# CM41x_M4 register map
Vendor: Analog Devices; Series: CM41x_M4; File version: 1p0
CPU: CM4 r0p1, little endian, MPU, FPU, 4 interrupt priority bits
Registers are 32-bit, read-write, reset 0x0 unless marked. A register's access mark holds for its fields unless they carry their own. Offsets are from the block's base; [hi:lo] are bit positions; {n}, {i} and the like mark numbered series.

## SMC0 — Static Memory Controller
Base 0x4002F000
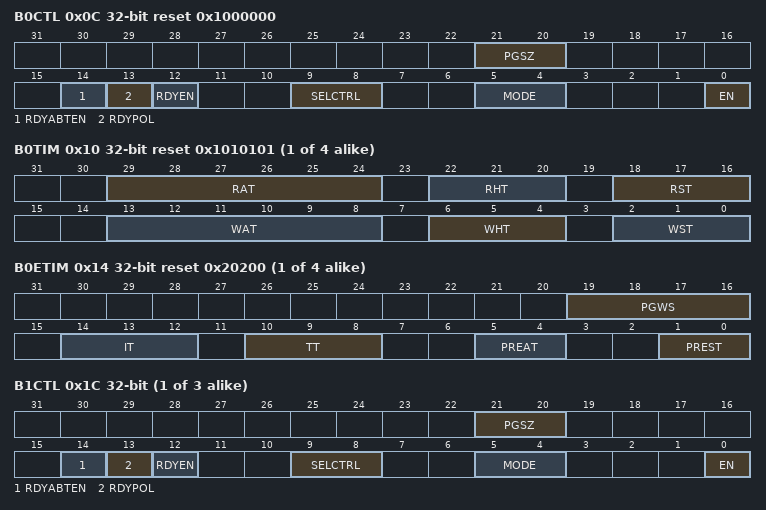
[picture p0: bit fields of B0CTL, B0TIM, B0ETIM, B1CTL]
0x0C B0CTL reset 0x1000000 — Bank 0 Control Register
  [21:20] PGSZ — Flash Page Size
  [14] RDYABTEN — ARDY Abort Enable
  [13] RDYPOL — ARDY Polarity
  [12] RDYEN — ARDY Enable
  [9:8] SELCTRL — Select Control
  [5:4] MODE — Memory Access Mode
  [0] EN — Bank 0 Enable
{0x10+0x10*i} B{i}TIM reset 0x1010101 (i=0..3) — Bank {i} Timing Register
  [29:24] RAT — Read Access Time
  [22:20] RHT — Read Hold Time
  [18:16] RST — Read Setup Time
  [13:8] WAT — Write Access Time
  [6:4] WHT — Write Hold Time
  [2:0] WST — Write Setup Time
{0x14+0x10*i} B{i}ETIM reset 0x20200 (i=0..3) — Bank {i} Extended Timing Register
  [19:16] PGWS — Page Wait States
  [14:12] IT — Idle Time
  [10:8] TT — Transition Time
  [5:4] PREAT — Pre Access Time
  [1:0] PREST — Pre Setup Time
{0xC+0x10*i} B{i}CTL (i=1..3) — Bank {i} Control Register
  [21:20] PGSZ — Flash Page Size
  [14] RDYABTEN — ARDY Abort Enable
  [13] RDYPOL — ARDY Polarity
  [12] RDYEN — ARDY Enable
  [9:8] SELCTRL — Select Control
  [5:4] MODE — Memory Access Mode
  [0] EN — Bank {i} Enable

## DACC0 — DAC Controller
Base 0x4004B000
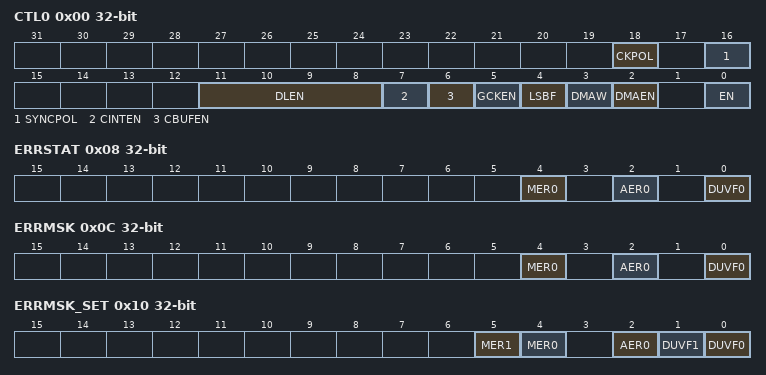
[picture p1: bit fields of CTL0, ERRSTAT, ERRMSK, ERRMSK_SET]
0x00 CTL0 — Control 0 Register
  [18] CKPOL — Clock Polarity
  [16] SYNCPOL — SYNC Polarity
  [11:8] DLEN range 0x00000000..0x0000000F — Data Length
  [7] CINTEN — Circular Buffer Interrupt Enable
  [6] CBUFEN — Circular Buffer Enable
  [5] GCKEN — Gated Clock Enable
  [4] LSBF — LSB-First Mode
  [3] DMAW — DMA Data Width
  [2] DMAEN — DMA Enable
  [0] EN — Enable
0x08 ERRSTAT — Error Status Register
  [4] MER0 — Memory Error 0
  [2] AER0 — Address Alignment Error 0
  [0] DUVF0 — DAC0 Underflow
0x0C ERRMSK — Error Mask Register
  [4] MER0 — Memory Error 0 Mask
  [2] AER0 — Address Alignment Error 0 Mask
  [0] DUVF0 — DAC Underflow 0 Mask
0x10 ERRMSK_SET — Error Mask Set Register
  [5] MER1 range 0x00000000..0x00000001 — Memory Error 1 Mask Set
  [4] MER0 range 0x00000000..0x00000001 — Memory Error 0 Mask Set
  [2] AER0 range 0x00000000..0x00000001 — Address Alignment Error 0 Mask Set
  [1] DUVF1 range 0x00000000..0x00000001 — DAC Underflow 1 Mask Set
  [0] DUVF0 range 0x00000000..0x00000001 — DAC Underflow 0 Mask Set
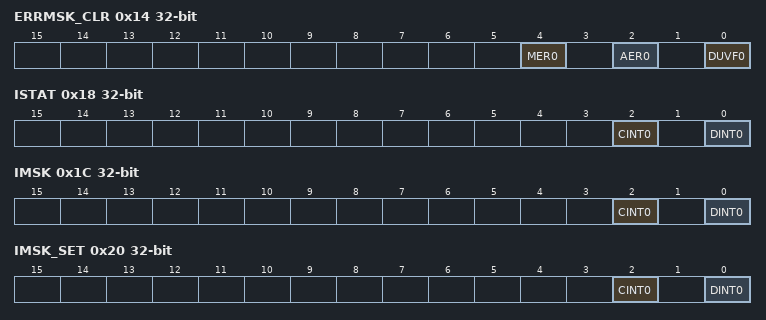
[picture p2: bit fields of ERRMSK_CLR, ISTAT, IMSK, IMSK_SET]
0x14 ERRMSK_CLR — Error Mask Clear Register
  [4] MER0 range 0x00000000..0x00000001 — Memory Error 0 Mask Clear
  [2] AER0 range 0x00000000..0x00000001 — Address Alignment Error 0 Mask Clear
  [0] DUVF0 range 0x00000000..0x00000001 — DAC Underflow 0 Mask Clear
0x18 ISTAT — Interrupt Status Register
  [2] CINT0 ro — Core Complete (Non-DMA) Interrupt 0
  [0] DINT0 — DMA Complete Interrupt 0
0x1C IMSK — Interrupt Mask Register
  [2] CINT0 — Core Complete (Non-DMA) Interrupt 0 Mask
  [0] DINT0 — DMA Complete Interrupt 0 Mask
0x20 IMSK_SET — Interrupt Mask Set Register
  [2] CINT0 range 0x00000000..0x00000001 — Core Complete (Non-DMA) Interrupt 0 Mask Set
  [0] DINT0 range 0x00000000..0x00000001 — DMA Complete Interrupt 0 Mask Set
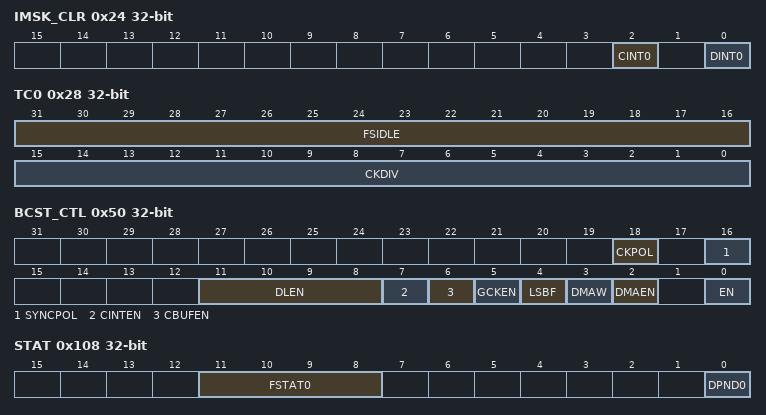
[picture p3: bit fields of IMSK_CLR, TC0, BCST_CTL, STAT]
0x24 IMSK_CLR — Interrupt Mask Clear Register
  [2] CINT0 range 0x00000000..0x00000001 — Core Complete (Non-DMA) Interrupt 0 Mask Clear.
  [0] DINT0 range 0x00000000..0x00000001 — DMA Complete Interrupt 0 Mask Clear
0x28 TC0 — Timing Control 0 Register
  [31:16] FSIDLE range 0x00000000..0x0000FFFF — Frame Sync Idle
  [15:0] CKDIV range 0x00000000..0x0000FFFF — Clock Divisor
0x2C BPTR0 — Base Pointer 0 Register
  [31:0] VALUE range 0x00000000..0xFFFFFFFF — Base Pointer 0 Value
0x30 MOD0 — Modify 0 Register
  [31:0] VALUE range 0x00000000..0xFFFFFFFF — Modify 0 Value
0x34 CNT0 — Count 0 Register
  [31:0] VALUE range 0x00000000..0xFFFFFFFF — Count 0 Value
0x38 DAT0 — Data FIFO 0 Register
  [15:0] VALUE range 0x00000000..0x0000FFFF — Data FIFO 0 Value
0x50 BCST_CTL — Broadcast (Write) Control Register
  [18] CKPOL range 0x00000000..0x00000001 — Clock Polarity
  [16] SYNCPOL range 0x00000000..0x00000001 — SYNC Polarity
  [11:8] DLEN range 0x00000000..0x0000000F — Data Length
  [7] CINTEN range 0x00000000..0x00000001 — Circular Buffer Interrupt Enable
  [6] CBUFEN range 0x00000000..0x00000001 — Circular Buffer Enable
  [5] GCKEN range 0x00000000..0x00000001 — Gated Clock Enable
  [4] LSBF range 0x00000000..0x00000001 — LSB-First Mode
  [3] DMAW range 0x00000000..0x00000001 — DMA Data Width
  [2] DMAEN range 0x00000000..0x00000001 — DMA Enable
  [0] EN range 0x00000000..0x00000001 — Enable
0x100 CNTCUR0 — Current Count 0 Register
  [31:0] VALUE ro — Current Count Value
0x108 STAT — Status Register
  [11:8] FSTAT0 ro — FIFO Status 0
  [0] DPND0 ro — Data Pending 0
